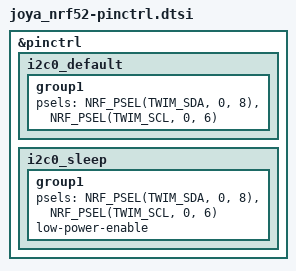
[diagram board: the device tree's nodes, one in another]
#include <zephyr/dt-bindings/pinctrl/nrf-pinctrl.h>

&pinctrl {
	i2c0_default: i2c0_default {
		group1 {
			psels = <NRF_PSEL(TWIM_SDA, 0, 8)>,
				<NRF_PSEL(TWIM_SCL, 0, 6)>;

			// Remove internal pull-up resistor
		};
	};

	i2c0_sleep: i2c0_sleep {
		group1 {
			psels = <NRF_PSEL(TWIM_SDA, 0, 8)>,
				<NRF_PSEL(TWIM_SCL, 0, 6)>;
			low-power-enable;
		};
	};
};
